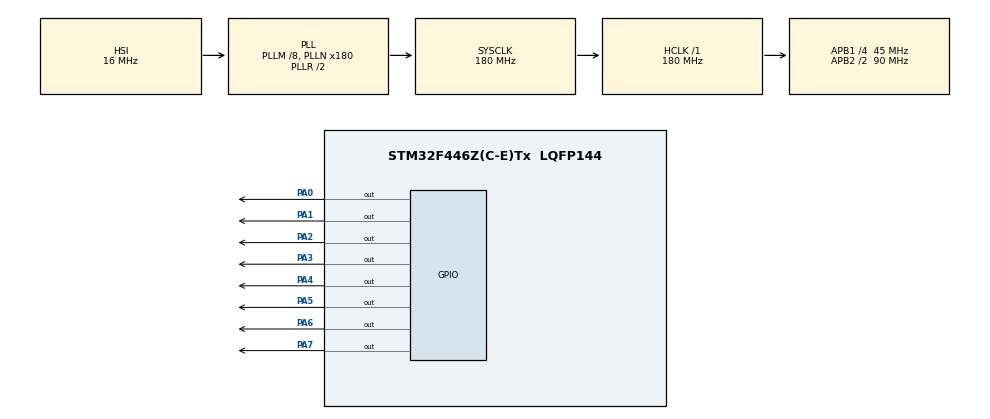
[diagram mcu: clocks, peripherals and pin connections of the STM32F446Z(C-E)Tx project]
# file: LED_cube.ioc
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Mcu.Family=STM32F4
Mcu.Name=STM32F446Z(C-E)Tx
Mcu.Package=LQFP144
NVIC.PriorityGroup=NVIC_PRIORITYGROUP_4
PA0-WKUP.GPIO_Speed=GPIO_SPEED_FREQ_VERY_HIGH
PA0-WKUP.PinState=GPIO_PIN_RESET
PA0-WKUP.Signal=GPIO_Output
PA1.GPIO_Speed=GPIO_SPEED_FREQ_VERY_HIGH
PA1.Signal=GPIO_Output
PA2.GPIO_Speed=GPIO_SPEED_FREQ_VERY_HIGH
PA2.PinState=GPIO_PIN_RESET
PA2.Signal=GPIO_Output
PA3.GPIO_PuPd=GPIO_NOPULL
PA3.GPIO_Speed=GPIO_SPEED_FREQ_VERY_HIGH
PA3.PinState=GPIO_PIN_RESET
PA3.Signal=GPIO_Output
PA4.GPIO_Speed=GPIO_SPEED_FREQ_VERY_HIGH
PA4.PinState=GPIO_PIN_RESET
PA4.Signal=GPIO_Output
PA5.GPIO_Speed=GPIO_SPEED_FREQ_VERY_HIGH
PA5.Signal=GPIO_Output
PA6.GPIO_Speed=GPIO_SPEED_FREQ_VERY_HIGH
PA6.Signal=GPIO_Output
PA7.GPIO_Speed=GPIO_SPEED_FREQ_VERY_HIGH
PA7.Signal=GPIO_Output
ProjectManager.HeapSize=0x200
ProjectManager.StackSize=0x400
ProjectManager.TargetToolchain=STM32CubeIDE
RCC.AHBFreq_Value=180000000
RCC.APB1CLKDivider=RCC_HCLK_DIV4
RCC.APB1Freq_Value=45000000
RCC.APB1TimFreq_Value=90000000
RCC.APB2CLKDivider=RCC_HCLK_DIV2
RCC.APB2Freq_Value=90000000
RCC.APB2TimFreq_Value=180000000
RCC.CortexFreq_Value=180000000
RCC.HCLKFreq_Value=180000000
RCC.PLLM=8
RCC.PLLN=180
RCC.SYSCLKFreq_VALUE=180000000
RCC.SYSCLKSource=RCC_SYSCLKSOURCE_PLLRCLK
RCC.USBFreq_Value=180000000
RCC.VCOOutputFreq_Value=360000000
TIM1.Period=0xffff-1
TIM1.Prescaler=1-1
VP_TIM1_VS_ClockSourceINT.Mode=Internal
board=custom

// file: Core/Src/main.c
/* USER CODE BEGIN Header */
/**
  ******************************************************************************
  * @file           : main.c
  * @brief          : Main program body
  ******************************************************************************
  * @attention
  *
  * Copyright (c) 2023 STMicroelectronics.
  * All rights reserved.
  *
  * This software is licensed under terms that can be found in the LICENSE file
  * in the root directory of this software component.
  * If no LICENSE file comes with this software, it is provided AS-IS.
  *
  ******************************************************************************
  */
/* USER CODE END Header */
#include "main.h"

/* USER CODE BEGIN Includes */
#include "LED_cube.h"
/* USER CODE END Includes */

TIM_HandleTypeDef htim1;

void SystemClock_Config(void);
static void MX_GPIO_Init(void);
static void MX_TIM1_Init(void);

int main(void)
{

  /* MCU Configuration--------------------------------------------------------*/

  /* Reset of all peripherals, Initializes the Flash interface and the Systick. */
  HAL_Init();

  /* Configure the system clock */
  SystemClock_Config();

  /* Initialize all configured peripherals */
  MX_GPIO_Init();
  MX_TIM1_Init();
  /* USER CODE BEGIN 2 */
  HAL_TIM_Base_Start(&htim1);

  uint8_t cube_colors[CUBE_MASSIVE_SIZE];
  cube_set_zero(cube_colors);
  stdin_set_params();
  /* USER CODE END 2 */

  /* Infinite loop */
  /* USER CODE BEGIN WHILE */
  while(1) {
	  get_cube(cube_colors);
	  send_cube(cube_colors);
    /* USER CODE END WHILE */

  }
}

void SystemClock_Config(void)
{
  RCC_OscInitTypeDef RCC_OscInitStruct = {0};
  RCC_ClkInitTypeDef RCC_ClkInitStruct = {0};

  /** Configure the main internal regulator output voltage
  */
  __HAL_RCC_PWR_CLK_ENABLE();
  __HAL_PWR_VOLTAGESCALING_CONFIG(PWR_REGULATOR_VOLTAGE_SCALE1);

  /** Initializes the RCC Oscillators according to the specified parameters
  * in the RCC_OscInitTypeDef structure.
  */
  RCC_OscInitStruct.OscillatorType = RCC_OSCILLATORTYPE_HSI;
  RCC_OscInitStruct.HSIState = RCC_HSI_ON;
  RCC_OscInitStruct.HSICalibrationValue = RCC_HSICALIBRATION_DEFAULT;
  RCC_OscInitStruct.PLL.PLLState = RCC_PLL_ON;
  RCC_OscInitStruct.PLL.PLLSource = RCC_PLLSOURCE_HSI;
  RCC_OscInitStruct.PLL.PLLM = 8;
  RCC_OscInitStruct.PLL.PLLN = 180;
  RCC_OscInitStruct.PLL.PLLP = RCC_PLLP_DIV2;
  RCC_OscInitStruct.PLL.PLLQ = 2;
  RCC_OscInitStruct.PLL.PLLR = 2;
  if (HAL_RCC_OscConfig(&RCC_OscInitStruct) != HAL_OK)
  {
    Error_Handler();
  }

  /** Activate the Over-Drive mode
  */
  if (HAL_PWREx_EnableOverDrive() != HAL_OK)
  {
    Error_Handler();
  }

  /** Initializes the CPU, AHB and APB buses clocks
  */
  RCC_ClkInitStruct.ClockType = RCC_CLOCKTYPE_HCLK|RCC_CLOCKTYPE_SYSCLK
                              |RCC_CLOCKTYPE_PCLK1|RCC_CLOCKTYPE_PCLK2;
  RCC_ClkInitStruct.SYSCLKSource = RCC_SYSCLKSOURCE_PLLRCLK;
  RCC_ClkInitStruct.AHBCLKDivider = RCC_SYSCLK_DIV1;
  RCC_ClkInitStruct.APB1CLKDivider = RCC_HCLK_DIV4;
  RCC_ClkInitStruct.APB2CLKDivider = RCC_HCLK_DIV2;

  if (HAL_RCC_ClockConfig(&RCC_ClkInitStruct, FLASH_LATENCY_5) != HAL_OK)
  {
    Error_Handler();
  }
}

static void MX_TIM1_Init(void)
{

  TIM_ClockConfigTypeDef sClockSourceConfig = {0};
  TIM_MasterConfigTypeDef sMasterConfig = {0};

  htim1.Instance = TIM1;
  htim1.Init.Prescaler = 1-1;
  htim1.Init.CounterMode = TIM_COUNTERMODE_UP;
  htim1.Init.Period = 0xffff-1;
  htim1.Init.ClockDivision = TIM_CLOCKDIVISION_DIV1;
  htim1.Init.RepetitionCounter = 0;
  htim1.Init.AutoReloadPreload = TIM_AUTORELOAD_PRELOAD_DISABLE;
  if (HAL_TIM_Base_Init(&htim1) != HAL_OK)
  {
    Error_Handler();
  }
  sClockSourceConfig.ClockSource = TIM_CLOCKSOURCE_INTERNAL;
  if (HAL_TIM_ConfigClockSource(&htim1, &sClockSourceConfig) != HAL_OK)
  {
    Error_Handler();
  }
  sMasterConfig.MasterOutputTrigger = TIM_TRGO_RESET;
  sMasterConfig.MasterSlaveMode = TIM_MASTERSLAVEMODE_DISABLE;
  if (HAL_TIMEx_MasterConfigSynchronization(&htim1, &sMasterConfig) != HAL_OK)
  {
    Error_Handler();
  }

}

static void MX_GPIO_Init(void)
{
  GPIO_InitTypeDef GPIO_InitStruct = {0};

  /* GPIO Ports Clock Enable */
  __HAL_RCC_GPIOA_CLK_ENABLE();

  /*Configure GPIO pin Output Level */
  HAL_GPIO_WritePin(GPIOA, GPIO_PIN_0|GPIO_PIN_1|GPIO_PIN_2|GPIO_PIN_3
                          |GPIO_PIN_4|GPIO_PIN_5|GPIO_PIN_6|GPIO_PIN_7, GPIO_PIN_RESET);

  /*Configure GPIO pins : PA0 PA1 PA2 PA3
                           PA4 PA5 PA6 PA7 */
  GPIO_InitStruct.Pin = GPIO_PIN_0|GPIO_PIN_1|GPIO_PIN_2|GPIO_PIN_3
                          |GPIO_PIN_4|GPIO_PIN_5|GPIO_PIN_6|GPIO_PIN_7;
  GPIO_InitStruct.Mode = GPIO_MODE_OUTPUT_PP;
  GPIO_InitStruct.Pull = GPIO_NOPULL;
  GPIO_InitStruct.Speed = GPIO_SPEED_FREQ_VERY_HIGH;
  HAL_GPIO_Init(GPIOA, &GPIO_InitStruct);

}

void Error_Handler(void)
{
  __disable_irq();
  while (1)
  {
  }
}
